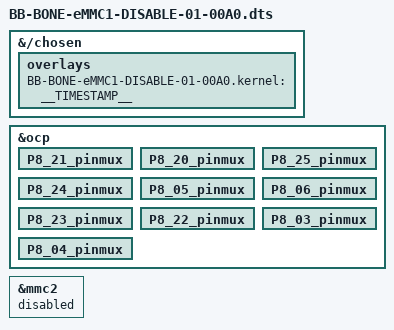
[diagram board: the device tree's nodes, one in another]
// SPDX-License-Identifier: GPL-2.0-only
/*
 * Copyright (C) 2012 Texas Instruments Incorporated - https://www.ti.com/
 */

/dts-v1/;
/plugin/;

/*
 * Helper to show loaded overlays under: /proc/device-tree/chosen/overlays/
 */
&{/chosen} {
	overlays {
		BB-BONE-eMMC1-DISABLE-01-00A0.kernel = __TIMESTAMP__;
	};
};

/*
 * Free up the pins used by the cape from the pinmux helpers.
 */
&ocp {
	P8_21_pinmux { status = "okay"; };	/* mmc1_clk */
	P8_20_pinmux { status = "okay"; };	/* mmc1_cmd */
	P8_25_pinmux { status = "okay"; };	/* mmc1_dat0 */
	P8_24_pinmux { status = "okay"; };	/* mmc1_dat1 */
	P8_05_pinmux { status = "okay"; };	/* mmc1_dat2 */
	P8_06_pinmux { status = "okay"; };	/* mmc1_dat3 */
	P8_23_pinmux { status = "okay"; };	/* mmc1_dat4 */
	P8_22_pinmux { status = "okay"; };	/* mmc1_dat5 */
	P8_03_pinmux { status = "okay"; };	/* mmc1_dat6 */
	P8_04_pinmux { status = "okay"; };	/* mmc1_dat7 */
};

&mmc2 {
	status = "disabled";
};
